# MKV31F25612 register map
Vendor: Freescale Semiconductor, Inc.; Series: Kinetis_V; File version: 1.6
CPU: CM4 r0p1, little endian, no MPU, FPU, VTOR, 4 interrupt priority bits
Registers are 32-bit, read-write, reset 0x0 unless marked. A register's access mark holds for its fields unless they carry their own. Offsets are from the block's base; [hi:lo] are bit positions; {n}, {i} and the like mark numbered series.

## RFSYS — System register file
Base 0x40041000; register names take the prefix RFSYS_
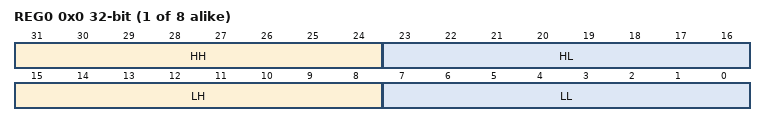
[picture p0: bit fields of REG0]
{0x0+4i} REG{i} (i=0..7) — Register file register
  [31:24] HH, [23:16] HL, [15:8] LH, [7:0] LL

## WDOG — Generation 2008 Watchdog Timer
Base 0x40052000; register names take the prefix WDOG_
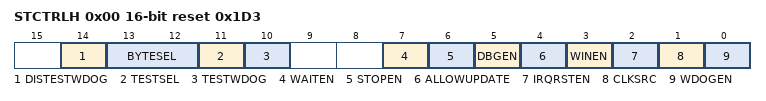
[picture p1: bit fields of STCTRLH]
0x00 STCTRLH 16-bit reset 0x1D3 — Watchdog Status and Control Register High
  [14] DISTESTWDOG
    0=WDOG functional test mode is not disabled; 1=WDOG functional test mode is disabled permanently until reset
  [13:12] BYTESEL
    {v}=Byte {v} selected (v=0..3)
  [11] TESTSEL
    0=Quick test. The timer runs in normal operation. You can load a small time-out value to do a quick test.; 1=Byte test. Puts the timer in the byte test mode where individual bytes of the timer are enabled for operation and are compared for time-out against the corresponding byte of the programmed time-out value. Select the byte through BYTESEL[1:0] for testing.
  [10] TESTWDOG
  [7] WAITEN
    0=WDOG is disabled in CPU Wait mode; 1=WDOG is enabled in CPU Wait mode
  [6] STOPEN
    0=WDOG is disabled in CPU Stop mode; 1=WDOG is enabled in CPU Stop mode
  [5] DBGEN
    0=WDOG is disabled in CPU Debug mode; 1=WDOG is enabled in CPU Debug mode
  [4] ALLOWUPDATE
    0=No further updates allowed to WDOG write-once registers; 1=WDOG write-once registers can be unlocked for updating
  [3] WINEN
    0=Windowing mode is disabled; 1=Windowing mode is enabled
  [2] IRQRSTEN
    0=WDOG time-out generates reset only; 1=WDOG time-out initially generates an interrupt. After WCT, it generates a reset.
  [1] CLKSRC
    0=WDOG clock sourced from LPO ; 1=WDOG clock sourced from alternate clock source
  [0] WDOGEN
    0=WDOG is disabled; 1=WDOG is enabled
0x02 STCTRLL 16-bit reset 0x1 — Watchdog Status and Control Register Low
  [15] INTFLG
0x04 TOVALH 16-bit reset 0x4C — Watchdog Time-out Value Register High
  [15:0] TOVALHIGH
0x06 TOVALL 16-bit reset 0x4B4C — Watchdog Time-out Value Register Low
  [15:0] TOVALLOW
0x08 WINH 16-bit — Watchdog Window Register High
  [15:0] WINHIGH
0x0A WINL 16-bit reset 0x10 — Watchdog Window Register Low
  [15:0] WINLOW
0x0C REFRESH 16-bit reset 0xB480 — Watchdog Refresh register
  [15:0] WDOGREFRESH
0x0E UNLOCK 16-bit reset 0xD928 — Watchdog Unlock register
  [15:0] WDOGUNLOCK
0x10 TMROUTH 16-bit — Watchdog Timer Output Register High
  [15:0] TIMEROUTHIGH
0x12 TMROUTL 16-bit — Watchdog Timer Output Register Low
  [15:0] TIMEROUTLOW
0x14 RSTCNT 16-bit — Watchdog Reset Count register
0x16 PRESC 16-bit reset 0x400 — Watchdog Prescaler register
  [10:8] PRESCVAL

## EWM — External Watchdog Monitor
Base 0x40061000; register names take the prefix EWM_
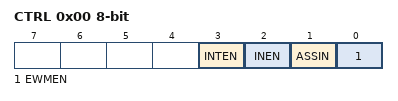
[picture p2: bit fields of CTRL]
0x00 CTRL 8-bit — Control Register
  [3] INTEN — Interrupt Enable.
  [2] INEN — Input Enable.
  [1] ASSIN — EWM_in's Assertion State Select.
  [0] EWMEN — EWM enable.
0x01 SERV 8-bit wo — Service Register
  [7:0] SERVICE
0x02 CMPL 8-bit — Compare Low Register
  [7:0] COMPAREL
0x03 CMPH 8-bit reset 0xFF — Compare High Register
  [7:0] COMPAREH
0x05 CLKPRESCALER 8-bit — Clock Prescaler Register
  [7:0] CLK_DIV

## OSC — Oscillator
Base 0x40065000; register names take the prefix OSC_
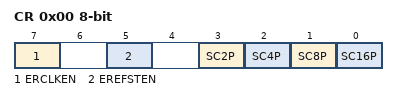
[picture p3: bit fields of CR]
0x00 CR 8-bit — OSC Control Register
  [7] ERCLKEN — External Reference Enable
    0=External reference clock is inactive; 1=External reference clock is enabled
  [5] EREFSTEN — External Reference Stop Enable
    0=External reference clock is disabled in Stop mode; 1=External reference clock stays enabled in Stop mode if ERCLKEN is set before entering Stop mode
  [3] SC2P — Oscillator 2 pF Capacitor Load Configure
    0=Disable the selection; 1=Add 2 pF capacitor to the oscillator load
  [2] SC4P — Oscillator 4 pF Capacitor Load Configure
    0=Disable the selection; 1=Add 4 pF capacitor to the oscillator load
  [1] SC8P — Oscillator 8 pF Capacitor Load Configure
    0=Disable the selection; 1=Add 8 pF capacitor to the oscillator load
  [0] SC16P — Oscillator 16 pF Capacitor Load Configure
    0=Disable the selection; 1=Add 16 pF capacitor to the oscillator load
0x02 DIV 8-bit — OSC_DIV
  [7:6] ERPS
    0=The divisor ratio is 1; 1=The divisor ratio is 2; 2=The divisor ratio is 4; 3=The divisor ratio is 8

## Notices in the file
Redistribution and use in source and binary forms, with or without modification,
are permitted provided that the following conditions are met:
o Redistributions of source code must retain the above copyright notice, this list
of conditions and the following disclaimer.
o Redistributions in binary form must reproduce the above copyright notice, this
list of conditions and the following disclaimer in the documentation and/or
other materials provided with the distribution.
o Neither the name of Freescale Semiconductor, Inc. nor the names of its
contributors may be used to endorse or promote products derived from this
software without specific prior written permission.
THIS SOFTWARE IS PROVIDED BY THE COPYRIGHT HOLDERS AND CONTRIBUTORS "AS IS" AND
ANY EXPRESS OR IMPLIED WARRANTIES, INCLUDING, BUT NOT LIMITED TO, THE IMPLIED
WARRANTIES OF MERCHANTABILITY AND FITNESS FOR A PARTICULAR PURPOSE ARE
DISCLAIMED. IN NO EVENT SHALL THE COPYRIGHT HOLDER OR CONTRIBUTORS BE LIABLE FOR
ANY DIRECT, INDIRECT, INCIDENTAL, SPECIAL, EXEMPLARY, OR CONSEQUENTIAL DAMAGES
(INCLUDING, BUT NOT LIMITED TO, PROCUREMENT OF SUBSTITUTE GOODS OR SERVICES;
LOSS OF USE, DATA, OR PROFITS; OR BUSINESS INTERRUPTION) HOWEVER CAUSED AND ON
ANY THEORY OF LIABILITY, WHETHER IN CONTRACT, STRICT LIABILITY, OR TORT
(INCLUDING NEGLIGENCE OR OTHERWISE) ARISING IN ANY WAY OUT OF THE USE OF THIS
SOFTWARE, EVEN IF ADVISED OF THE POSSIBILITY OF SUCH DAMAGE.
